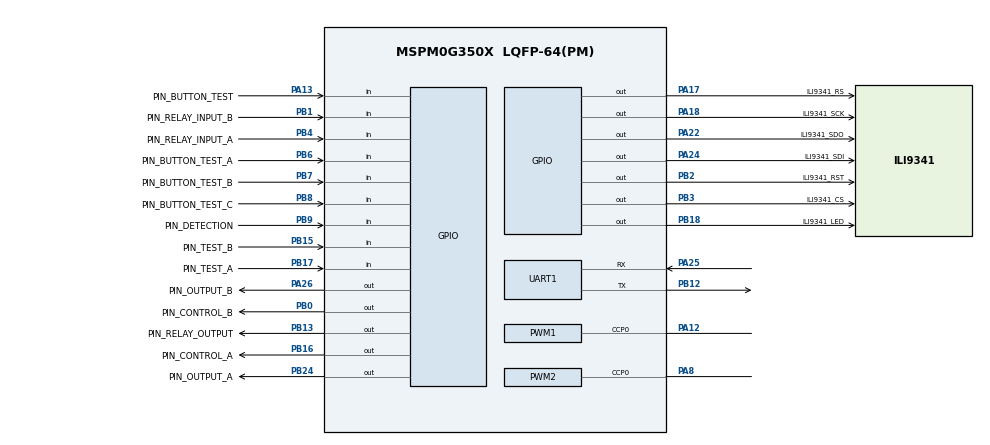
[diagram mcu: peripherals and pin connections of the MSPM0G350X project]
/**
 * @cliArgs --device "MSPM0G350X" --part "Default" --package "LQFP-64(PM)" --product "mspm0_sdk@2.09.00.00"
 * @versions {"tool":"1.26.0+4407"}
 */

/**
 * Import the modules used in this configuration.
 */
const ADC12         = scripting.addModule("/ti/driverlib/ADC12", {}, false);
const ADC121        = ADC12.addInstance();
const ADC122        = ADC12.addInstance();
const DAC12         = scripting.addModule("/ti/driverlib/DAC12");
const GPIO          = scripting.addModule("/ti/driverlib/GPIO", {}, false);
const GPIO1         = GPIO.addInstance();
const GPIO2         = GPIO.addInstance();
const GPIO3         = GPIO.addInstance();
const GPIO4         = GPIO.addInstance();
const GPIO5         = GPIO.addInstance();
const GPIO6         = GPIO.addInstance();
const PWM           = scripting.addModule("/ti/driverlib/PWM", {}, false);
const PWM1          = PWM.addInstance();
const PWM2          = PWM.addInstance();
const SYSCTL        = scripting.addModule("/ti/driverlib/SYSCTL");
const TIMER         = scripting.addModule("/ti/driverlib/TIMER", {}, false);
const TIMER1        = TIMER.addInstance();
const TIMER2        = TIMER.addInstance();
const UART          = scripting.addModule("/ti/driverlib/UART", {}, false);
const UART1         = UART.addInstance();
const ProjectConfig = scripting.addModule("/ti/project_config/ProjectConfig");

/**
 * Write custom configuration values to the imported modules.
 */
ADC121.$name                             = "ADC12_0";
ADC121.configureDMA                      = true;
ADC121.enabledDMATriggers                = ["DL_ADC12_DMA_MEM0_RESULT_LOADED"];
ADC121.repeatMode                        = true;
ADC121.powerDownMode                     = "DL_ADC12_POWER_DOWN_MODE_MANUAL";
ADC121.sampleTime0                       = "62.5ns";
ADC121.sampCnt                           = 1;
ADC121.trigSrc                           = "DL_ADC12_TRIG_SRC_EVENT";
ADC121.subChanID                         = 1;
ADC121.adcMem0trig                       = "DL_ADC12_TRIGGER_MODE_TRIGGER_NEXT";
ADC121.enabledInterrupts                 = ["DL_ADC12_INTERRUPT_DMA_DONE"];
ADC121.adcMem0chansel                    = "DL_ADC12_INPUT_CHAN_6";
ADC121.DMA_CHANNEL.$name                 = "DMA_CH0";
ADC121.DMA_CHANNEL.addressMode           = "f2b";
ADC121.DMA_CHANNEL.srcLength             = "HALF_WORD";
ADC121.DMA_CHANNEL.dstLength             = "HALF_WORD";
ADC121.DMA_CHANNEL.configureTransferSize = true;
ADC121.DMA_CHANNEL.transferSize          = 200;
ADC121.DMA_CHANNEL.transferMode          = "FULL_CH_REPEAT_SINGLE";
ADC121.peripheral.$assign                = "ADC0";
ADC121.peripheral.adcPin6.$assign        = "PB20";
ADC121.adcPin6Config.$name               = "ti_driverlib_gpio_GPIOPinGeneric0";

ADC122.$name                             = "ADC12_1";
ADC122.repeatMode                        = true;
ADC122.trigSrc                           = "DL_ADC12_TRIG_SRC_EVENT";
ADC122.adcMem0chansel                    = "DL_ADC12_INPUT_CHAN_6";
ADC122.powerDownMode                     = "DL_ADC12_POWER_DOWN_MODE_MANUAL";
ADC122.sampleTime0                       = "62.5ns";
ADC122.enabledInterrupts                 = ["DL_ADC12_INTERRUPT_DMA_DONE"];
ADC122.configureDMA                      = true;
ADC122.sampCnt                           = 1;
ADC122.enabledDMATriggers                = ["DL_ADC12_DMA_MEM0_RESULT_LOADED"];
ADC122.subChanID                         = 2;
ADC122.adcMem0trig                       = "DL_ADC12_TRIGGER_MODE_TRIGGER_NEXT";
ADC122.peripheral.$assign                = "ADC1";
ADC122.peripheral.adcPin6.$assign        = "PB19";
ADC122.adcPin6Config.$name               = "ti_driverlib_gpio_GPIOPinGeneric5";
ADC122.DMA_CHANNEL.$name                 = "DMA_CH1";
ADC122.DMA_CHANNEL.srcLength             = "HALF_WORD";
ADC122.DMA_CHANNEL.dstLength             = "HALF_WORD";
ADC122.DMA_CHANNEL.addressMode           = "f2b";
ADC122.DMA_CHANNEL.configureTransferSize = true;
ADC122.DMA_CHANNEL.transferSize          = 200;
ADC122.DMA_CHANNEL.transferMode          = "FULL_CH_REPEAT_SINGLE";

const Board = scripting.addModule("/ti/driverlib/Board", {}, false);

DAC12.dacAmplifier       = "ON";
DAC12.dacOutputPinEn     = true;
DAC12.OutPinConfig.$name = "ti_driverlib_gpio_GPIOPinGeneric2";

GPIO1.$name                         = "GPIO";
GPIO1.associatedPins.create(7);
GPIO1.associatedPins[0].$name       = "ILI9341_CS";
GPIO1.associatedPins[0].pin.$assign = "PB3";
GPIO1.associatedPins[1].$name       = "ILI9341_RST";
GPIO1.associatedPins[1].pin.$assign = "PB2";
GPIO1.associatedPins[2].$name       = "ILI9341_RS";
GPIO1.associatedPins[2].pin.$assign = "PA17";
GPIO1.associatedPins[3].$name       = "ILI9341_SDI";
GPIO1.associatedPins[3].pin.$assign = "PA24";
GPIO1.associatedPins[4].$name       = "ILI9341_SCK";
GPIO1.associatedPins[4].pin.$assign = "PA18";
GPIO1.associatedPins[5].$name       = "ILI9341_LED";
GPIO1.associatedPins[5].pin.$assign = "PB18";
GPIO1.associatedPins[6].$name       = "ILI9341_SDO";
GPIO1.associatedPins[6].pin.$assign = "PA22";

GPIO2.$name                              = "GPIO_TRIGGER_LEVEL";
GPIO2.associatedPins[0].direction        = "INPUT";
GPIO2.associatedPins[0].$name            = "PIN_DETECTION";
GPIO2.associatedPins[0].interruptEn      = true;
GPIO2.associatedPins[0].polarity         = "FALL";
GPIO2.associatedPins[0].internalResistor = "PULL_UP";
GPIO2.associatedPins[0].pin.$assign      = "PB9";

GPIO3.$name                              = "GPIO_ENCODER";
GPIO3.port                               = "PORTB";
GPIO3.associatedPins.create(2);
GPIO3.associatedPins[0].$name            = "PIN_TEST_A";
GPIO3.associatedPins[0].direction        = "INPUT";
GPIO3.associatedPins[0].internalResistor = "PULL_UP";
GPIO3.associatedPins[0].interruptEn      = true;
GPIO3.associatedPins[0].polarity         = "FALL";
GPIO3.associatedPins[0].pin.$assign      = "PB17";
GPIO3.associatedPins[1].$name            = "PIN_TEST_B";
GPIO3.associatedPins[1].direction        = "INPUT";
GPIO3.associatedPins[1].internalResistor = "PULL_UP";
GPIO3.associatedPins[1].pin.$assign      = "PB15";

GPIO4.$name                              = "GPIO_RESPONSIVENESS";
GPIO4.associatedPins.create(5);
GPIO4.associatedPins[0].$name            = "PIN_BUTTON_TEST_A";
GPIO4.associatedPins[0].direction        = "INPUT";
GPIO4.associatedPins[0].internalResistor = "PULL_UP";
GPIO4.associatedPins[0].pin.$assign      = "PB6";
GPIO4.associatedPins[1].$name            = "PIN_BUTTON_TEST_B";
GPIO4.associatedPins[1].direction        = "INPUT";
GPIO4.associatedPins[1].internalResistor = "PULL_UP";
GPIO4.associatedPins[1].pin.$assign      = "PB7";
GPIO4.associatedPins[2].$name            = "PIN_BUTTON_TEST_C";
GPIO4.associatedPins[2].direction        = "INPUT";
GPIO4.associatedPins[2].internalResistor = "PULL_UP";
GPIO4.associatedPins[2].pin.$assign      = "PB8";
GPIO4.associatedPins[3].$name            = "PIN_CONTROL_A";
GPIO4.associatedPins[3].pin.$assign      = "PB16";
GPIO4.associatedPins[4].$name            = "PIN_CONTROL_B";
GPIO4.associatedPins[4].pin.$assign      = "PB0";

GPIO5.$name                              = "GPIO_CORRECT";
GPIO5.associatedPins.create(3);
GPIO5.associatedPins[0].direction        = "INPUT";
GPIO5.associatedPins[0].$name            = "PIN_BUTTON_TEST";
GPIO5.associatedPins[0].internalResistor = "PULL_UP";
GPIO5.associatedPins[0].pin.$assign      = "PA13";
GPIO5.associatedPins[1].$name            = "PIN_OUTPUT_A";
GPIO5.associatedPins[1].pin.$assign      = "PB24";
GPIO5.associatedPins[2].$name            = "PIN_OUTPUT_B";
GPIO5.associatedPins[2].pin.$assign      = "PA26";

GPIO6.$name                              = "GPIO_RELAY";
GPIO6.associatedPins.create(3);
GPIO6.associatedPins[0].direction        = "INPUT";
GPIO6.associatedPins[0].internalResistor = "PULL_UP";
GPIO6.associatedPins[0].$name            = "PIN_RELAY_INPUT_A";
GPIO6.associatedPins[0].pin.$assign      = "PB4";
GPIO6.associatedPins[1].$name            = "PIN_RELAY_INPUT_B";
GPIO6.associatedPins[1].direction        = "INPUT";
GPIO6.associatedPins[1].internalResistor = "PULL_UP";
GPIO6.associatedPins[1].pin.$assign      = "PB1";
GPIO6.associatedPins[2].$name            = "PIN_RELAY_OUTPUT";
GPIO6.associatedPins[2].pin.$assign      = "PB13";

PWM1.$name                      = "PWM_0";
PWM1.timerCount                 = 32000;
PWM1.ccIndex                    = [0];
PWM1.PWM_CHANNEL_0.$name        = "ti_driverlib_pwm_PWMTimerCC0";
PWM1.PWM_CHANNEL_0.dutyCycle    = 50;
PWM1.ccp0PinConfig.$name        = "ti_driverlib_gpio_GPIOPinGeneric1";
PWM1.peripheral.$assign         = "TIMG0";
PWM1.peripheral.ccp0Pin.$assign = "PA12";

PWM2.$name                      = "PWM_1";
PWM2.timerCount                 = 32000;
PWM2.ccIndex                    = [0];
PWM2.PWM_CHANNEL_0.$name        = "ti_driverlib_pwm_PWMTimerCC1";
PWM2.PWM_CHANNEL_0.dutyCycle    = 50;
PWM2.ccp0PinConfig.$name        = "ti_driverlib_gpio_GPIOPinGeneric6";
PWM2.peripheral.ccp0Pin.$assign = "PA8";

SYSCTL.forceDefaultClkConfig = true;
SYSCTL.MFPCLKEn              = true;

TIMER1.$name            = "TIMER_0";
TIMER1.timerMode        = "PERIODIC";
TIMER1.timerPeriod      = "10ms";
TIMER1.timerClkPrescale = 10;
TIMER1.interrupts       = ["ZERO"];

TIMER2.$name                       = "TIMER_1";
TIMER2.timerMode                   = "PERIODIC";
TIMER2.timerStartTimer             = true;
TIMER2.interrupts                  = ["ZERO"];
TIMER2.event1PublisherChannel      = 1;
TIMER2.event1ControllerInterruptEn = ["ZERO_EVENT"];
TIMER2.timerPeriod                 = "500ns";
TIMER2.event2ControllerInterruptEn = ["ZERO_EVENT"];
TIMER2.event2PublisherChannel      = 2;

UART1.$name                            = "UART_BT";
UART1.enabledInterrupts                = ["RX"];
UART1.peripheral.rxPin.$assign         = "PA25";
UART1.peripheral.txPin.$assign         = "PB12";
UART1.txPinConfig.direction            = scripting.forceWrite("OUTPUT");
UART1.txPinConfig.hideOutputInversion  = scripting.forceWrite(false);
UART1.txPinConfig.onlyInternalResistor = scripting.forceWrite(false);
UART1.txPinConfig.passedPeripheralType = scripting.forceWrite("Digital");
UART1.txPinConfig.$name                = "ti_driverlib_gpio_GPIOPinGeneric3";
UART1.rxPinConfig.hideOutputInversion  = scripting.forceWrite(false);
UART1.rxPinConfig.onlyInternalResistor = scripting.forceWrite(false);
UART1.rxPinConfig.passedPeripheralType = scripting.forceWrite("Digital");
UART1.rxPinConfig.$name                = "ti_driverlib_gpio_GPIOPinGeneric4";

ProjectConfig.genLibCMSIS = true;

/**
 * Pinmux solution for unlocked pins/peripherals. This ensures that minor changes to the automatic solver in a future
 * version of the tool will not impact the pinmux you originally saw.  These lines can be completely deleted in order to
 * re-solve from scratch.
 */
ADC121.DMA_CHANNEL.peripheral.$suggestSolution = "DMA_CH1";
ADC122.DMA_CHANNEL.peripheral.$suggestSolution = "DMA_CH0";
Board.peripheral.$suggestSolution              = "DEBUGSS";
Board.peripheral.swclkPin.$suggestSolution     = "PA20";
Board.peripheral.swdioPin.$suggestSolution     = "PA19";
DAC12.peripheral.$suggestSolution              = "DAC0";
DAC12.peripheral.OutPin.$suggestSolution       = "PA15";
PWM2.peripheral.$suggestSolution               = "TIMA0";
SYSCTL.peripheral.$suggestSolution             = "SYSCTL";
TIMER1.peripheral.$suggestSolution             = "TIMG6";
TIMER2.peripheral.$suggestSolution             = "TIMA1";
UART1.peripheral.$suggestSolution              = "UART3";
